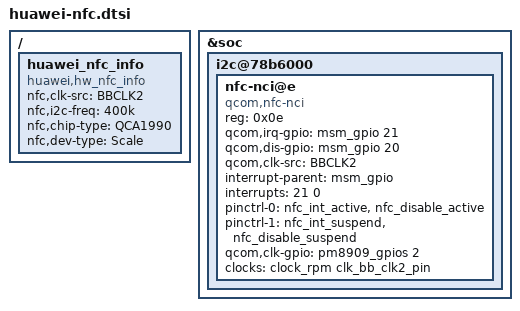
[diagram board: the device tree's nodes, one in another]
 / {
        huawei_nfc_info {
                compatible = "huawei,hw_nfc_info";
                nfc,clk-src = "BBCLK2";
                nfc,i2c-freq = "400k";
                nfc,chip-type = "QCA1990";
                nfc,dev-type = "Scale";
                status = "ok";
        };
};


&soc {
		i2c@78b6000 { /* BLSP1 QUP2 */
			nfc-nci@e {
				compatible = "qcom,nfc-nci";
				reg = <0x0e>;
				qcom,irq-gpio = <&msm_gpio 21 0x00>;
				qcom,dis-gpio = <&msm_gpio 20 0x00>;
				qcom,clk-src = "BBCLK2";
				interrupt-parent = <&msm_gpio>;
				interrupts = <21 0>;
				interrupt-names = "nfc_irq";
				pinctrl-names = "nfc_active","nfc_suspend";
				pinctrl-0 = <&nfc_int_active &nfc_disable_active>;
				pinctrl-1 = <&nfc_int_suspend &nfc_disable_suspend>;
				qcom,clk-gpio = <&pm8909_gpios 2 0>;
				clocks = <&clock_rpm clk_bb_clk2_pin>;
				clock-names = "ref_clk";
			};
		};
};


